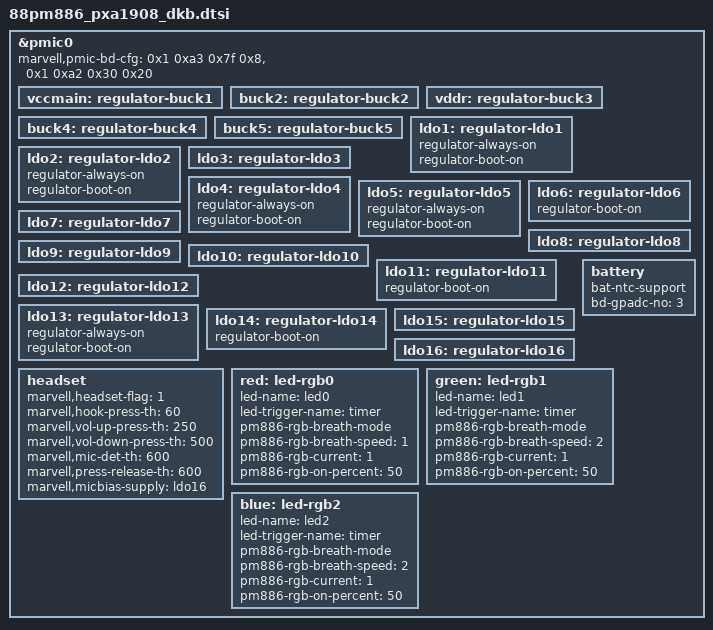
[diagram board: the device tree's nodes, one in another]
/*
 * Copyright (C) 2014 Marvell
 * Yi Zhang <yizhang@marvell.com>
 */

/*
 * Integrated Power Management Chip: 88pm886
 * header file for pxa1908_dkb
 */

&pmic0 {
	/*
	 * board specific configuration
	 * use value directly, not use macro
	 * <page reg-addr mask value>
	 */
	marvell,pmic-bd-cfg = <0x1 0xa3 0x7f 0x8>,
			      <0x1 0xa2 0x30 0x20>;

	/* ---buck--- */
	vccmain: regulator-buck1 {
	};
	buck2: regulator-buck2 {
	};
	vddr: regulator-buck3 {
	};
	buck4: regulator-buck4 {
	};
	buck5: regulator-buck5 {
	};

	/* ---ldo--- */
	ldo1: regulator-ldo1 {
		regulator-always-on;
		regulator-boot-on;
	};
	ldo2: regulator-ldo2 {
		regulator-always-on;
		regulator-boot-on;
	};
	ldo3: regulator-ldo3 {
	};
	ldo4: regulator-ldo4 {
		regulator-always-on;
		regulator-boot-on;
	};
	ldo5: regulator-ldo5 {
		regulator-always-on;
		regulator-boot-on;
	};
	ldo6: regulator-ldo6 {
		regulator-boot-on;
	};
	ldo7: regulator-ldo7 {
	};
	ldo8: regulator-ldo8 {
	};
	ldo9: regulator-ldo9 {
	};
	ldo10: regulator-ldo10 {
	};
	ldo11: regulator-ldo11 { /* ldo11 is enabled in uboot for LCD */
	        regulator-boot-on;
	};
	ldo12: regulator-ldo12 {
	};
	ldo13: regulator-ldo13 {
		regulator-always-on;
		regulator-boot-on;
	};
	ldo14: regulator-ldo14 {
		regulator-boot-on;
	};
	ldo15: regulator-ldo15 {
	};
	ldo16: regulator-ldo16 {
	};

	headset {
		marvell,headset-flag = <1>;
		marvell,hook-press-th = <60>;
		marvell,vol-up-press-th = <250>;
		marvell,vol-down-press-th = <500>;
		marvell,mic-det-th = <600>;
		marvell,press-release-th = <600>;
		marvell,micbias-supply = <&ldo16>;
		status = "okay";
	};

	battery {
		bat-ntc-support;
		bd-gpadc-no = <3>;
	};

	red: led-rgb0 {
	       led-name = "led0";
	       led-trigger-name = "timer";
	       pm886-rgb-breath-mode;
	       pm886-rgb-breath-speed = <1>;

	       pm886-rgb-current = /bits/ 8 <1>; /* 8 mA */
	       pm886-rgb-on-percent = /bits/ 8 <50>;

       };

	green: led-rgb1 {
	       led-name = "led1";
	       led-trigger-name = "timer";
	       pm886-rgb-breath-mode;
	       pm886-rgb-breath-speed = <2>;

	       pm886-rgb-current = /bits/ 8 <1>; /* 8 mA */
	       pm886-rgb-on-percent = /bits/ 8 <50>;
       };

	blue: led-rgb2 {
	       led-name = "led2";
	       led-trigger-name = "timer";
	       pm886-rgb-breath-mode;
	       pm886-rgb-breath-speed = <2>;

	       pm886-rgb-current = /bits/ 8 <1>; /* 8 mA */
	       pm886-rgb-on-percent = /bits/ 8 <50>;
       };
};
